# ionuc505 register map
Registers are 32-bit, access not given, no defined reset value unless marked. A register's access mark holds for its fields unless they carry their own. Addresses are absolute; registers are grouped by the start of their names; [hi:lo] are bit positions; {n}, {i} and the like mark numbered series; 'fields as' and 'values as' point back to an identical list.

## NVIC
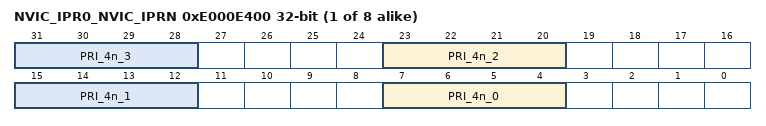
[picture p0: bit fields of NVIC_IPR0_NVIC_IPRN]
{0xE000E400+4i} NVIC_IPR{i}_NVIC_IPRN (i=0..7)
  [8n+7:8n+4] PRI_4n_{n} (n=0..3)

## CLK
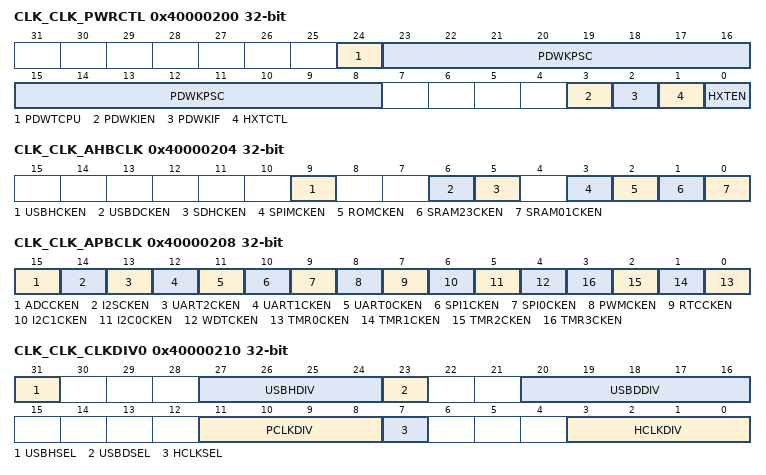
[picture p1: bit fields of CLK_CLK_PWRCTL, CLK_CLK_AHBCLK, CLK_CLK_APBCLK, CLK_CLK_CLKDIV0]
0x40000200 CLK_CLK_PWRCTL
  [24] PDWTCPU, [23:8] PDWKPSC, [3] PDWKIEN, [2] PDWKIF, [1] HXTCTL, [0] HXTEN
0x40000204 CLK_CLK_AHBCLK
  [9] USBHCKEN, [6] USBDCKEN, [5] SDHCKEN, [3] SPIMCKEN, [2] ROMCKEN, [1] SRAM23CKEN, [0] SRAM01CKEN
0x40000208 CLK_CLK_APBCLK
  [15] ADCCKEN, [14] I2SCKEN, [13] UART2CKEN, [12] UART1CKEN, [11] UART0CKEN, [10] SPI1CKEN, [9] SPI0CKEN, [8] PWMCKEN, [7] RTCCKEN, [6] I2C1CKEN, [5] I2C0CKEN, [4] WDTCKEN, [n] TMR{n}CKEN (n=0..3)
0x40000210 CLK_CLK_CLKDIV0
  [31] USBHSEL, [27:24] USBHDIV, [23] USBDSEL, [20:16] USBDDIV, [11:8] PCLKDIV, [7] HCLKSEL, [3:0] HCLKDIV
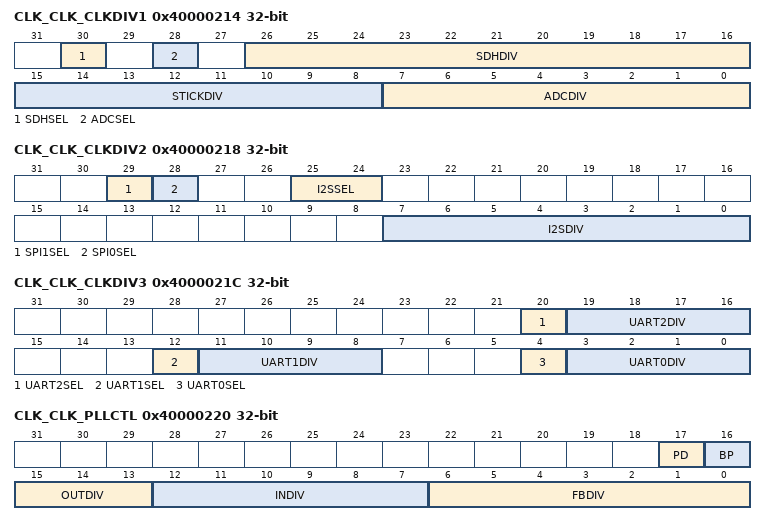
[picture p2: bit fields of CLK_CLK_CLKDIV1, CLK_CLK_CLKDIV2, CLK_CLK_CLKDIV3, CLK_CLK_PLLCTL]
0x40000214 CLK_CLK_CLKDIV1
  [30] SDHSEL, [28] ADCSEL, [26:16] SDHDIV, [15:8] STICKDIV, [7:0] ADCDIV
0x40000218 CLK_CLK_CLKDIV2
  [29] SPI1SEL, [28] SPI0SEL, [25:24] I2SSEL, [7:0] I2SDIV
0x4000021C CLK_CLK_CLKDIV3
  [20] UART2SEL, [19:16] UART2DIV, [12] UART1SEL, [11:8] UART1DIV, [4] UART0SEL, [3:0] UART0DIV
0x40000220 CLK_CLK_PLLCTL
  [17] PD, [16] BP, [15:13] OUTDIV, [12:7] INDIV, [6:0] FBDIV
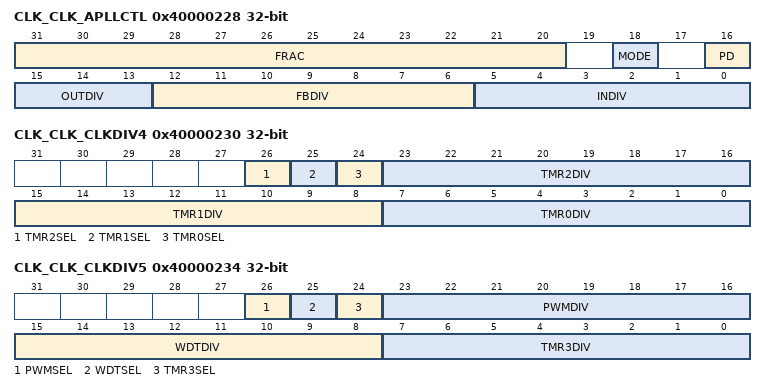
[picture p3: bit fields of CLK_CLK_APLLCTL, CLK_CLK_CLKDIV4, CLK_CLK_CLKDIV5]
0x40000228 CLK_CLK_APLLCTL
  [31:20] FRAC, [18] MODE, [16] PD, [15:13] OUTDIV, [12:6] FBDIV, [5:0] INDIV
0x40000230 CLK_CLK_CLKDIV4
  [26] TMR2SEL, [25] TMR1SEL, [24] TMR0SEL, [23:16] TMR2DIV, [15:8] TMR1DIV, [7:0] TMR0DIV
0x40000234 CLK_CLK_CLKDIV5
  [26] PWMSEL, [25] WDTSEL, [24] TMR3SEL, [23:16] PWMDIV, [15:8] WDTDIV, [7:0] TMR3DIV

## GPIO
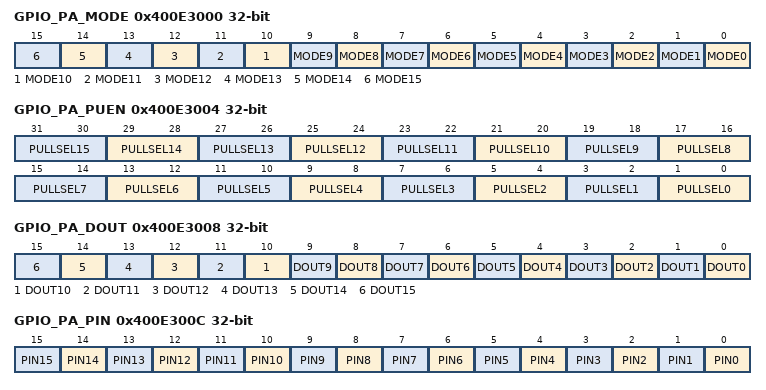
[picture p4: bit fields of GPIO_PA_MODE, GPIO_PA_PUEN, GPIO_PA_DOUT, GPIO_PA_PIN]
0x400E3000 GPIO_PA_MODE
  [n] MODE{n} (n=0..15)
0x400E3004 GPIO_PA_PUEN
  [2n+1:2n] PULLSEL{n} (n=0..15)
0x400E3008 GPIO_PA_DOUT
  [n] DOUT{n} (n=0..15)
0x400E300C GPIO_PA_PIN
  [n] PIN{n} (n=0..15)
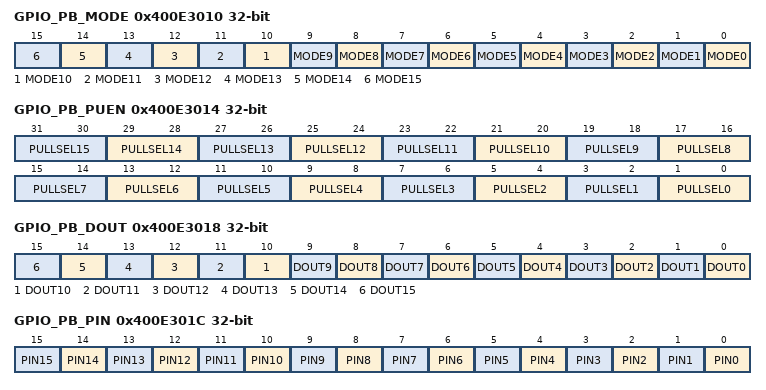
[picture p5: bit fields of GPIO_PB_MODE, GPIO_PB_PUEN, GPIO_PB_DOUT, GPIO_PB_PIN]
0x400E3010 GPIO_PB_MODE
  [n] MODE{n} (n=0..15)
0x400E3014 GPIO_PB_PUEN
  [2n+1:2n] PULLSEL{n} (n=0..15)
0x400E3018 GPIO_PB_DOUT
  [n] DOUT{n} (n=0..15)
0x400E301C GPIO_PB_PIN
  [n] PIN{n} (n=0..15)
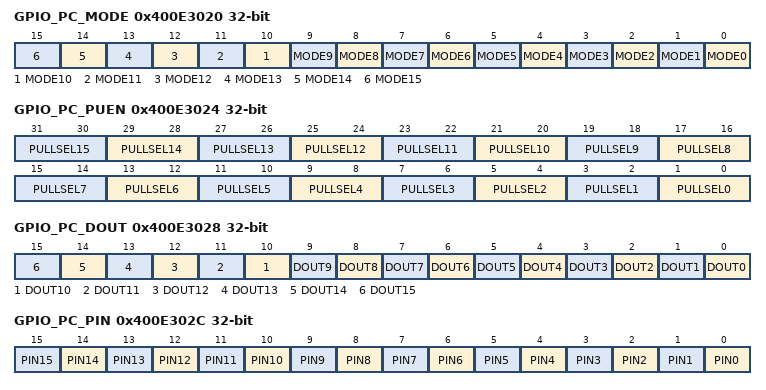
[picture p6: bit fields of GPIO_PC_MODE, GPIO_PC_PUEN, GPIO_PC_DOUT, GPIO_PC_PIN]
0x400E3020 GPIO_PC_MODE
  [n] MODE{n} (n=0..15)
0x400E3024 GPIO_PC_PUEN
  [2n+1:2n] PULLSEL{n} (n=0..15)
0x400E3028 GPIO_PC_DOUT
  [n] DOUT{n} (n=0..15)
0x400E302C GPIO_PC_PIN
  [n] PIN{n} (n=0..15)
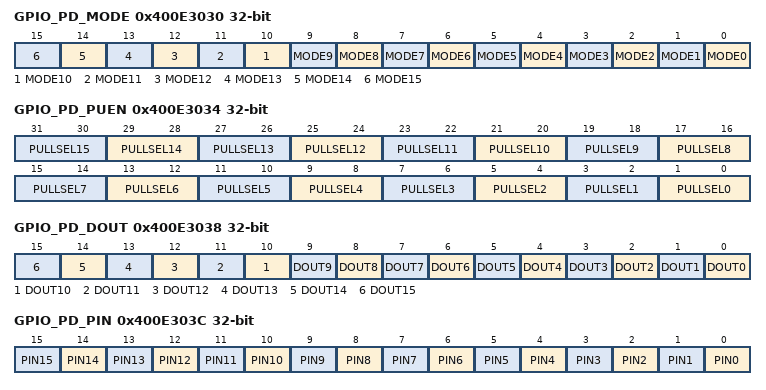
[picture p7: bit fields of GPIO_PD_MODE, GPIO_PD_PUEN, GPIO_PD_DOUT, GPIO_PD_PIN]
0x400E3030 GPIO_PD_MODE
  [n] MODE{n} (n=0..15)
0x400E3034 GPIO_PD_PUEN
  [2n+1:2n] PULLSEL{n} (n=0..15)
0x400E3038 GPIO_PD_DOUT
  [n] DOUT{n} (n=0..15)
0x400E303C GPIO_PD_PIN
  [n] PIN{n} (n=0..15)
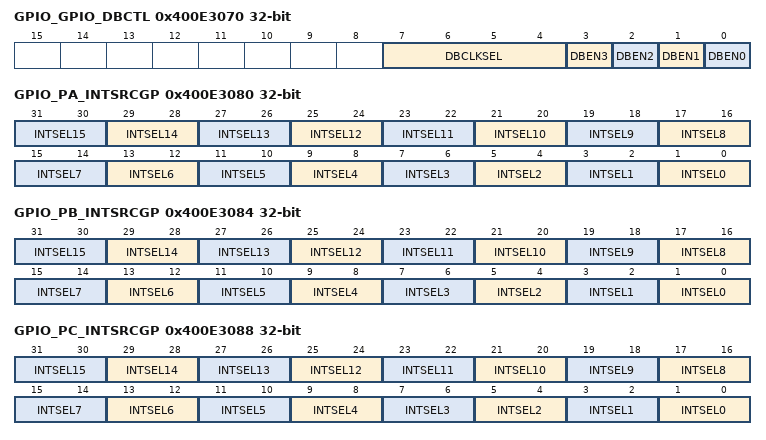
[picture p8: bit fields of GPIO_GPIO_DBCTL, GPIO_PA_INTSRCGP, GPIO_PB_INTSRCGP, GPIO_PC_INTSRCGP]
0x400E3070 GPIO_GPIO_DBCTL
  [7:4] DBCLKSEL, [n] DBEN{n} (n=0..3)
0x400E3080 GPIO_PA_INTSRCGP
  [2n+1:2n] INTSEL{n} (n=0..15)
0x400E3084 GPIO_PB_INTSRCGP
  [2n+1:2n] INTSEL{n} (n=0..15)
0x400E3088 GPIO_PC_INTSRCGP
  [2n+1:2n] INTSEL{n} (n=0..15)
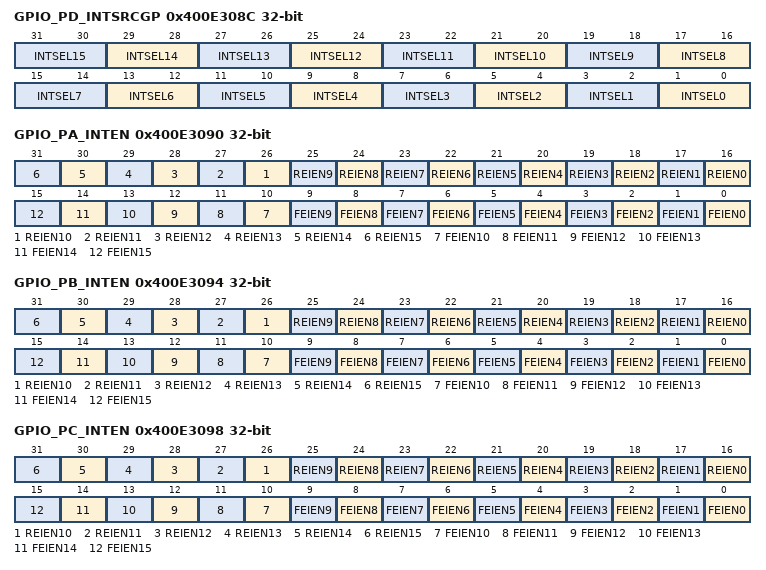
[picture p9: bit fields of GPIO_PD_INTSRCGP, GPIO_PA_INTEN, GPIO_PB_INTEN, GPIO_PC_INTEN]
0x400E308C GPIO_PD_INTSRCGP
  [2n+1:2n] INTSEL{n} (n=0..15)
0x400E3090 GPIO_PA_INTEN
  [n+16] REIEN{n} (n=0..15), [n] FEIEN{n} (n=0..15)
0x400E3094 GPIO_PB_INTEN
  [n+16] REIEN{n} (n=0..15), [n] FEIEN{n} (n=0..15)
0x400E3098 GPIO_PC_INTEN
  [n+16] REIEN{n} (n=0..15), [n] FEIEN{n} (n=0..15)
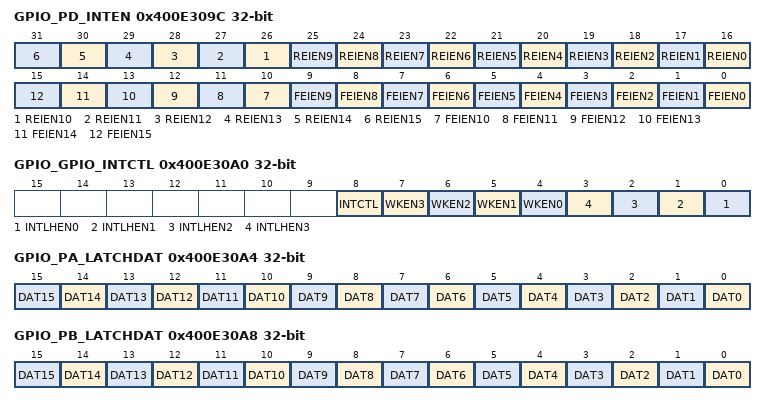
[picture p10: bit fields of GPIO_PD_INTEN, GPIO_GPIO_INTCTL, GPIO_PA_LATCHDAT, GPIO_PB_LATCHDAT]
0x400E309C GPIO_PD_INTEN
  [n+16] REIEN{n} (n=0..15), [n] FEIEN{n} (n=0..15)
0x400E30A0 GPIO_GPIO_INTCTL
  [8] INTCTL, [n+4] WKEN{n} (n=0..3), [n] INTLHEN{n} (n=0..3)
0x400E30A4 GPIO_PA_LATCHDAT
  [n] DAT{n} (n=0..15)
0x400E30A8 GPIO_PB_LATCHDAT
  [n] DAT{n} (n=0..15)
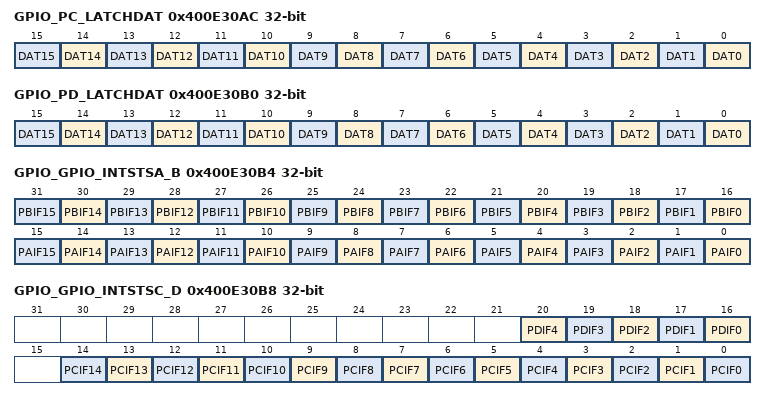
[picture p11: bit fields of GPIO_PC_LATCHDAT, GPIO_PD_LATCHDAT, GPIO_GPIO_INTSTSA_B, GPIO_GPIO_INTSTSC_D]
0x400E30AC GPIO_PC_LATCHDAT
  [n] DAT{n} (n=0..15)
0x400E30B0 GPIO_PD_LATCHDAT
  [n] DAT{n} (n=0..15)
0x400E30B4 GPIO_GPIO_INTSTSA_B
  [n+16] PBIF{n} (n=0..15), [n] PAIF{n} (n=0..15)
0x400E30B8 GPIO_GPIO_INTSTSC_D
  [n+16] PDIF{n} (n=0..4), [n] PCIF{n} (n=0..14)

## TIMER01
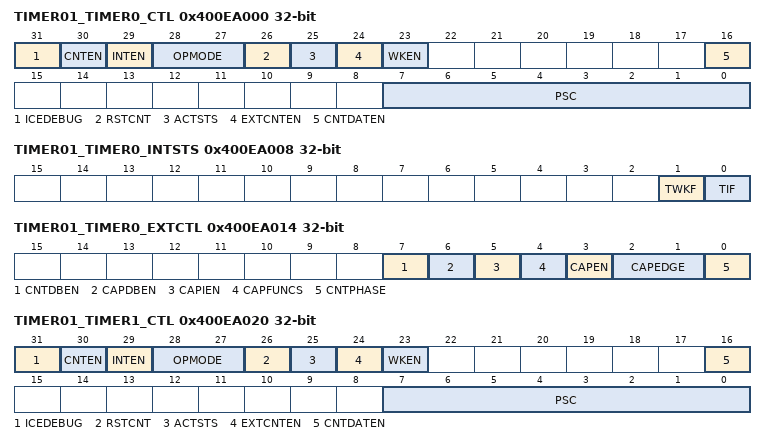
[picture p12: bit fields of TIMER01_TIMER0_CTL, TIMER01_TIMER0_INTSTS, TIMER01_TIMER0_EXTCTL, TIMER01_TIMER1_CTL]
0x400EA000 TIMER01_TIMER0_CTL
  [31] ICEDEBUG, [30] CNTEN, [29] INTEN, [28:27] OPMODE, [26] RSTCNT, [25] ACTSTS, [24] EXTCNTEN, [23] WKEN, [16] CNTDATEN, [7:0] PSC
0x400EA004 TIMER01_TIMER0_CMP
  [23:0] CMPDAT
0x400EA008 TIMER01_TIMER0_INTSTS
  [1] TWKF, [0] TIF
0x400EA00C TIMER01_TIMER0_CNT
  [23:0] CNT
0x400EA010 TIMER01_TIMER0_CAP
  [23:0] CAPDAT
0x400EA014 TIMER01_TIMER0_EXTCTL
  [7] CNTDBEN, [6] CAPDBEN, [5] CAPIEN, [4] CAPFUNCS, [3] CAPEN, [2:1] CAPEDGE, [0] CNTPHASE
0x400EA018 TIMER01_TIMER0_EINTSTS
  [0] CAPIF
0x400EA020 TIMER01_TIMER1_CTL
  fields as TIMER01_TIMER0_CTL
0x400EA024 TIMER01_TIMER1_CMP
  [23:0] CMPDAT
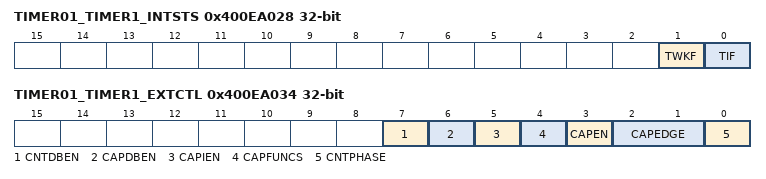
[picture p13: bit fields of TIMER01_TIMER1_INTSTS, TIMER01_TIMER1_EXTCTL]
0x400EA028 TIMER01_TIMER1_INTSTS
  [1] TWKF, [0] TIF
0x400EA02C TIMER01_TIMER1_CNT
  [23:0] CNT
0x400EA030 TIMER01_TIMER1_CAP
  [23:0] CAPDAT
0x400EA034 TIMER01_TIMER1_EXTCTL
  fields as TIMER01_TIMER0_EXTCTL
0x400EA038 TIMER01_TIMER1_EINTSTS
  [0] CAPIF
